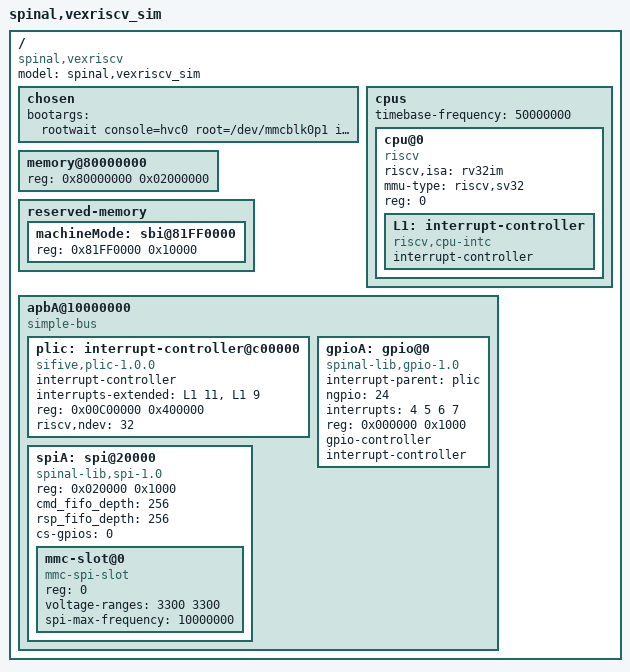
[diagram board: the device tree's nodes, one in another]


/dts-v1/;
//include/ "dt-bindings/interrupt-controller/irq.h"
//include/ "dt-bindings/gpio/gpio.h"



/ {
    #address-cells = <0x1>;
    #size-cells = <0x1>;
    compatible = "spinal,vexriscv";
    model = "spinal,vexriscv_sim";

    chosen {
        bootargs = "rootwait console=hvc0 root=/dev/mmcblk0p1 init=/sbin/init"; // loglevel=7
    };


    cpus {
        #address-cells = <0x1>;
        #size-cells = <0x0>;
        timebase-frequency = <50000000>;
            cpu@0 {
                device_type = "cpu";
                compatible = "riscv";
                riscv,isa = "rv32im";
                mmu-type = "riscv,sv32";
                reg = <0>;
                status = "okay";
                L1: interrupt-controller {
                    #interrupt-cells = <0x00000001>;
                    interrupt-controller;
                    compatible = "riscv,cpu-intc";
                };
            };
        };

    memory@80000000 {
        device_type = "memory";
        reg = <0x80000000 0x02000000>;
    };

	reserved-memory {
		#address-cells = <1>;
		#size-cells = <1>;
		ranges;

		machineMode: sbi@81FF0000 {
			reg = <0x81FF0000 0x10000>;
		};
	};

    apbA@10000000 {
        compatible = "simple-bus";
        #address-cells = <0x1>;
        #size-cells = <0x1>;
        ranges = <0x0 0x10000000 0x01000000>;

        plic: interrupt-controller@c00000 {
            compatible = "sifive,plic-1.0.0", "sifive,fu540-c000-plic";
            #interrupt-cells = <1>;
            interrupt-controller;
            interrupts-extended = <&L1 11 &L1 9>;
            reg = <0x00C00000 0x400000>;
            riscv,ndev = <32>;
        };

        gpioA: gpio@0 {
	        compatible = "spinal-lib,gpio-1.0";
	        interrupt-parent = <&plic>;
	        ngpio = <24>;
	        interrupts = <4 5 6 7>;
	        reg = <0x000000 0x1000>;
	        gpio-controller;
	        #gpio-cells = <2>;
	        interrupt-controller;
	        #interrupt-cells = <2>;
        };

        spiA: spi@20000 {
            compatible = "spinal-lib,spi-1.0";
            #address-cells = <1>;
            #size-cells = <0>;   
            reg = <0x020000 0x1000>;
            cmd_fifo_depth = <256>;
            rsp_fifo_depth = <256>;
            cs-gpios = <0>;

                   

            mmc-slot@0 {
                compatible = "mmc-spi-slot";
                reg = <0>;
                voltage-ranges = <3300 3300>;
                spi-max-frequency = <10000000>;
            };
        };
    };
};


